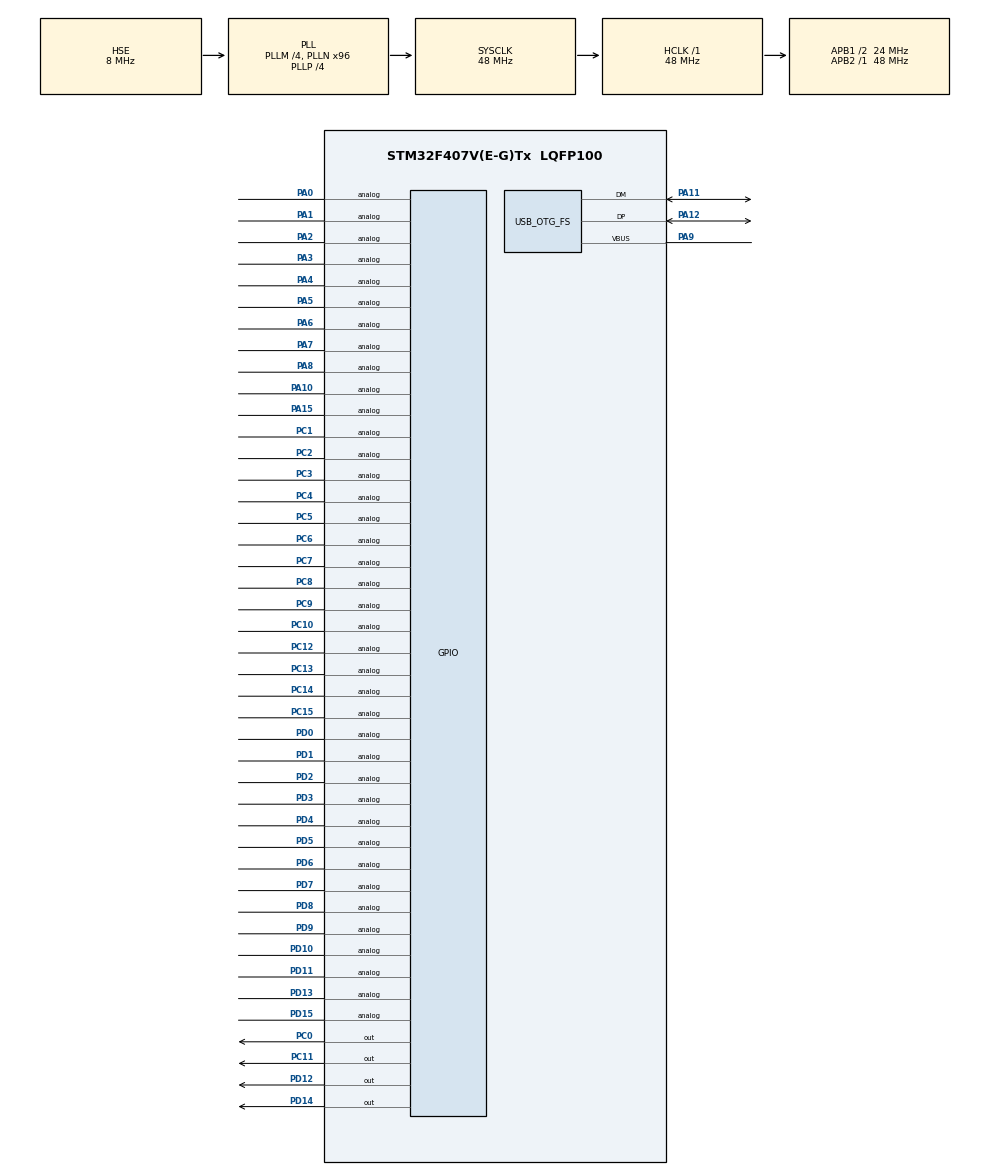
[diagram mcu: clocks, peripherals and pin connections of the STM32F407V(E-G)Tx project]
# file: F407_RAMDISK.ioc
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Mcu.Family=STM32F4
Mcu.Name=STM32F407V(E-G)Tx
Mcu.Package=LQFP100
NVIC.OTG_FS_IRQn=true\:0\:0\:false\:false\:true\:false\:true
NVIC.PriorityGroup=NVIC_PRIORITYGROUP_0
PA0-WKUP.Signal=GPIO_Analog
PA1.Signal=GPIO_Analog
PA10.Signal=GPIO_Analog
PA11.Mode=Device_Only
PA11.Signal=USB_OTG_FS_DM
PA12.Mode=Device_Only
PA12.Signal=USB_OTG_FS_DP
PA13.Mode=Serial_Wire
PA13.Signal=SYS_JTMS-SWDIO
PA14.Mode=Serial_Wire
PA14.Signal=SYS_JTCK-SWCLK
PA15.Signal=GPIO_Analog
PA2.Signal=GPIO_Analog
PA3.Signal=GPIO_Analog
PA4.Signal=GPIO_Analog
PA5.Signal=GPIO_Analog
PA6.Signal=GPIO_Analog
PA7.Signal=GPIO_Analog
PA8.Signal=GPIO_Analog
PA9.Mode=Activate_VBUS
PA9.Signal=USB_OTG_FS_VBUS
PC0.Signal=GPIO_Output
PC1.Signal=GPIO_Analog
PC10.Signal=GPIO_Analog
PC11.Signal=GPIO_Output
PC12.Signal=GPIO_Analog
PC13-ANTI_TAMP.Signal=GPIO_Analog
PC14-OSC32_IN.Signal=GPIO_Analog
PC15-OSC32_OUT.Signal=GPIO_Analog
PC2.Signal=GPIO_Analog
PC3.Signal=GPIO_Analog
PC4.Signal=GPIO_Analog
PC5.Signal=GPIO_Analog
PC6.Signal=GPIO_Analog
PC7.Signal=GPIO_Analog
PC8.Signal=GPIO_Analog
PC9.Signal=GPIO_Analog
PD0.Signal=GPIO_Analog
PD1.Signal=GPIO_Analog
PD10.Signal=GPIO_Analog
PD11.Signal=GPIO_Analog
PD12.Signal=GPIO_Output
PD13.Signal=GPIO_Analog
PD14.Signal=GPIO_Output
PD15.Signal=GPIO_Analog
PD2.Signal=GPIO_Analog
PD3.Signal=GPIO_Analog
PD4.Signal=GPIO_Analog
PD5.Signal=GPIO_Analog
PD6.Signal=GPIO_Analog
PD7.Signal=GPIO_Analog
PD8.Signal=GPIO_Analog
PD9.Signal=GPIO_Analog
PH0-OSC_IN.Mode=HSE-External-Oscillator
PH0-OSC_IN.Signal=RCC_OSC_IN
PH1-OSC_OUT.Mode=HSE-External-Oscillator
PH1-OSC_OUT.Signal=RCC_OSC_OUT
ProjectManager.HeapSize=0x400
ProjectManager.StackSize=0x400
ProjectManager.TargetToolchain=Makefile
RCC.48MHZClocksFreq_Value=48000000
RCC.AHBFreq_Value=48000000
RCC.APB1CLKDivider=RCC_HCLK_DIV2
RCC.APB1Freq_Value=24000000
RCC.APB1TimFreq_Value=48000000
RCC.APB2Freq_Value=48000000
RCC.APB2TimFreq_Value=48000000
RCC.CortexFreq_Value=48000000
RCC.HCLKFreq_Value=48000000
RCC.HSE_VALUE=8000000
RCC.HSI_VALUE=16000000
RCC.LSE_VALUE=32768
RCC.PLLM=4
RCC.PLLN=96
RCC.PLLP=RCC_PLLP_DIV4
RCC.SYSCLKFreq_VALUE=48000000
RCC.SYSCLKSource=RCC_SYSCLKSOURCE_PLLCLK
RCC.VCOOutputFreq_Value=192000000
USB_DEVICE.CLASS_NAME_FS=MSC
USB_DEVICE.VirtualMode-MSC_FS=Msc
USB_DEVICE.VirtualModeFS=Msc_FS
USB_OTG_FS.VirtualMode=Device_Only
VP_USB_DEVICE_VS_USB_DEVICE_MSC_FS.Mode=MSC_FS
board=STM32F4DISCOVERY

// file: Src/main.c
/* USER CODE BEGIN Header */
/**
  ******************************************************************************
  * @file           : main.c
  * @brief          : Main program body
  ******************************************************************************
  * @attention
  *
  * <h2><center>&copy; Copyright (c) 2019 STMicroelectronics.
  * All rights reserved.</center></h2>
  *
  * This software component is licensed by ST under Ultimate Liberty license
  * SLA0044, the "License"; You may not use this file except in compliance with
  * the License. You may obtain a copy of the License at:
  *                             www.st.com/SLA0044
  *
  ******************************************************************************
  */
/* USER CODE END Header */

#include "main.h"
#include "usb_device.h"

/* USER CODE BEGIN Includes */
void STORAGE_FileSystem_Init (void);
/* USER CODE END Includes */

void SystemClock_Config(void);
static void MX_GPIO_Init(void);

int main(void)
{

  /* MCU Configuration--------------------------------------------------------*/

  /* Reset of all peripherals, Initializes the Flash interface and the Systick. */
  HAL_Init();

  /* Configure the system clock */
  SystemClock_Config();

  /* USER CODE BEGIN SysInit */
  STORAGE_FileSystem_Init();
  /* USER CODE END SysInit */

  /* Initialize all configured peripherals */
  MX_GPIO_Init();
  MX_USB_DEVICE_Init();

  /* Infinite loop */
  while (1)
  {

  }
}

void SystemClock_Config(void)
{
  RCC_OscInitTypeDef RCC_OscInitStruct = {0};
  RCC_ClkInitTypeDef RCC_ClkInitStruct = {0};

  /** Configure the main internal regulator output voltage
  */
  __HAL_RCC_PWR_CLK_ENABLE();
  __HAL_PWR_VOLTAGESCALING_CONFIG(PWR_REGULATOR_VOLTAGE_SCALE1);
  /** Initializes the CPU, AHB and APB busses clocks
  */
  RCC_OscInitStruct.OscillatorType = RCC_OSCILLATORTYPE_HSE;
  RCC_OscInitStruct.HSEState = RCC_HSE_ON;
  RCC_OscInitStruct.PLL.PLLState = RCC_PLL_ON;
  RCC_OscInitStruct.PLL.PLLSource = RCC_PLLSOURCE_HSE;
  RCC_OscInitStruct.PLL.PLLM = 4;
  RCC_OscInitStruct.PLL.PLLN = 96;
  RCC_OscInitStruct.PLL.PLLP = RCC_PLLP_DIV4;
  RCC_OscInitStruct.PLL.PLLQ = 4;
  if (HAL_RCC_OscConfig(&RCC_OscInitStruct) != HAL_OK)
  {
    Error_Handler();
  }
  /** Initializes the CPU, AHB and APB busses clocks
  */
  RCC_ClkInitStruct.ClockType = RCC_CLOCKTYPE_HCLK|RCC_CLOCKTYPE_SYSCLK
                              |RCC_CLOCKTYPE_PCLK1|RCC_CLOCKTYPE_PCLK2;
  RCC_ClkInitStruct.SYSCLKSource = RCC_SYSCLKSOURCE_PLLCLK;
  RCC_ClkInitStruct.AHBCLKDivider = RCC_SYSCLK_DIV1;
  RCC_ClkInitStruct.APB1CLKDivider = RCC_HCLK_DIV2;
  RCC_ClkInitStruct.APB2CLKDivider = RCC_HCLK_DIV1;

  if (HAL_RCC_ClockConfig(&RCC_ClkInitStruct, FLASH_LATENCY_1) != HAL_OK)
  {
    Error_Handler();
  }
}

static void MX_GPIO_Init(void)
{
  GPIO_InitTypeDef GPIO_InitStruct = {0};

  /* GPIO Ports Clock Enable */
  __HAL_RCC_GPIOC_CLK_ENABLE();
  __HAL_RCC_GPIOH_CLK_ENABLE();
  __HAL_RCC_GPIOA_CLK_ENABLE();
  __HAL_RCC_GPIOD_CLK_ENABLE();

  /*Configure GPIO pin Output Level */
  HAL_GPIO_WritePin(GPIOC, GPIO_PIN_0|GPIO_PIN_11, GPIO_PIN_SET);

  /*Configure GPIO pin Output Level */
  HAL_GPIO_WritePin(GPIOD, GPIO_PIN_12|GPIO_PIN_14, GPIO_PIN_RESET);

  /*Configure GPIO pins : PC13 PC14 PC15 PC1
                           PC2 PC3 PC4 PC5
                           PC6 PC7 PC8 PC9
                           PC10 PC12 */
  GPIO_InitStruct.Pin = GPIO_PIN_13|GPIO_PIN_14|GPIO_PIN_15|GPIO_PIN_1
                          |GPIO_PIN_2|GPIO_PIN_3|GPIO_PIN_4|GPIO_PIN_5
                          |GPIO_PIN_6|GPIO_PIN_7|GPIO_PIN_8|GPIO_PIN_9
                          |GPIO_PIN_10|GPIO_PIN_12;
  GPIO_InitStruct.Mode = GPIO_MODE_ANALOG;
  GPIO_InitStruct.Pull = GPIO_NOPULL;
  HAL_GPIO_Init(GPIOC, &GPIO_InitStruct);

  /*Configure GPIO pins : PC0 PC11 */
  GPIO_InitStruct.Pin = GPIO_PIN_0|GPIO_PIN_11;
  GPIO_InitStruct.Mode = GPIO_MODE_OUTPUT_PP;
  GPIO_InitStruct.Pull = GPIO_NOPULL;
  GPIO_InitStruct.Speed = GPIO_SPEED_FREQ_LOW;
  HAL_GPIO_Init(GPIOC, &GPIO_InitStruct);

  /*Configure GPIO pins : PA0 PA1 PA2 PA3
                           PA4 PA5 PA6 PA7
                           PA8 PA10 PA15 */
  GPIO_InitStruct.Pin = GPIO_PIN_0|GPIO_PIN_1|GPIO_PIN_2|GPIO_PIN_3
                          |GPIO_PIN_4|GPIO_PIN_5|GPIO_PIN_6|GPIO_PIN_7
                          |GPIO_PIN_8|GPIO_PIN_10|GPIO_PIN_15;
  GPIO_InitStruct.Mode = GPIO_MODE_ANALOG;
  GPIO_InitStruct.Pull = GPIO_NOPULL;
  HAL_GPIO_Init(GPIOA, &GPIO_InitStruct);

  /*Configure GPIO pins : PD8 PD9 PD10 PD11
                           PD13 PD15 PD0 PD1
                           PD2 PD3 PD4 PD5
                           PD6 PD7 */
  GPIO_InitStruct.Pin = GPIO_PIN_8|GPIO_PIN_9|GPIO_PIN_10|GPIO_PIN_11
                          |GPIO_PIN_13|GPIO_PIN_15|GPIO_PIN_0|GPIO_PIN_1
                          |GPIO_PIN_2|GPIO_PIN_3|GPIO_PIN_4|GPIO_PIN_5
                          |GPIO_PIN_6|GPIO_PIN_7;
  GPIO_InitStruct.Mode = GPIO_MODE_ANALOG;
  GPIO_InitStruct.Pull = GPIO_NOPULL;
  HAL_GPIO_Init(GPIOD, &GPIO_InitStruct);

  /*Configure GPIO pins : PD12 PD14 */
  GPIO_InitStruct.Pin = GPIO_PIN_12|GPIO_PIN_14;
  GPIO_InitStruct.Mode = GPIO_MODE_OUTPUT_PP;
  GPIO_InitStruct.Pull = GPIO_NOPULL;
  GPIO_InitStruct.Speed = GPIO_SPEED_FREQ_LOW;
  HAL_GPIO_Init(GPIOD, &GPIO_InitStruct);

}

void Error_Handler(void)
{
}

/************************ (C) COPYRIGHT STMicroelectronics *****END OF FILE****/
